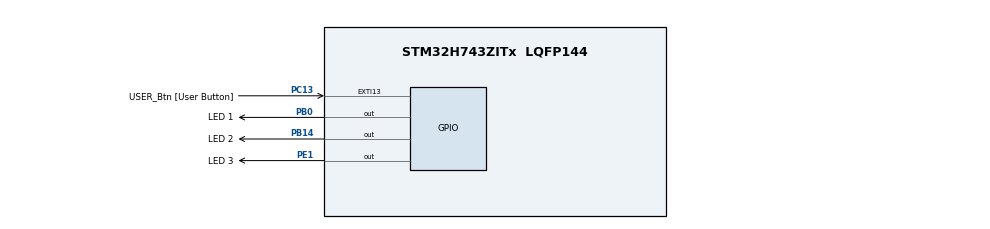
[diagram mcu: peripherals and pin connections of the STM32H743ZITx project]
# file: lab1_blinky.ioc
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CORTEX_M7.default_mode_Activation=1
Mcu.Family=STM32H7
Mcu.Name=STM32H743ZITx
Mcu.Package=LQFP144
NVIC.PriorityGroup=NVIC_PRIORITYGROUP_4
PA13\ (JTMS/SWDIO).GPIO_Label=TMS
PA13\ (JTMS/SWDIO).Signal=DEBUG_JTMS-SWDIO
PA14\ (JTCK/SWCLK).GPIO_Label=TCK
PA14\ (JTCK/SWCLK).Signal=DEBUG_JTCK-SWCLK
PB0.GPIO_Label=LED 1
PB0.GPIO_Speed=GPIO_SPEED_FREQ_HIGH
PB0.PinState=GPIO_PIN_SET
PB0.Signal=GPIO_Output
PB14.GPIO_Label=LED 2
PB14.GPIO_Speed=GPIO_SPEED_FREQ_HIGH
PB14.PinState=GPIO_PIN_SET
PB14.Signal=GPIO_Output
PB3\ (JTDO/TRACESWO).GPIO_Label=SWO
PB3\ (JTDO/TRACESWO).Signal=DEBUG_JTDO-SWO
PC13.GPIO_Label=USER_Btn [User Button]
PC13.Signal=GPXTI13
PC14-OSC32_IN\ (OSC32_IN).Signal=RCC_OSC32_IN
PC15-OSC32_OUT\ (OSC32_OUT).Signal=RCC_OSC32_OUT
PD8.GPIO_Label=STLK_RX [STM32F103CBT6_PA3]
PD8.Signal=USART3_TX
PD9.GPIO_Label=STLK_TX [STM32F103CBT6_PA2]
PD9.Signal=USART3_RX
PE1.GPIO_Label=LED 3
PE1.GPIO_Speed=GPIO_SPEED_FREQ_HIGH
PE1.PinState=GPIO_PIN_SET
PE1.Signal=GPIO_Output
PH0-OSC_IN\ (PH0).Mode=HSE-External-Oscillator
PH0-OSC_IN\ (PH0).Signal=RCC_OSC_IN
PH1-OSC_OUT\ (PH1).Mode=HSE-External-Oscillator
PH1-OSC_OUT\ (PH1).Signal=RCC_OSC_OUT
ProjectManager.HeapSize=0x200
ProjectManager.StackSize=0x400
ProjectManager.TargetToolchain=STM32CubeIDE
RCC.48MHZClocksFreq_Value=24000000
RCC.ADCFreq_Value=16125000
RCC.AHBFreq_Value=216000000
RCC.APB1CLKDivider=RCC_HCLK_DIV4
RCC.APB1Freq_Value=120000000
RCC.APB1TimFreq_Value=108000000
RCC.APB2CLKDivider=RCC_HCLK_DIV2
RCC.APB2Freq_Value=120000000
RCC.APB2TimFreq_Value=216000000
RCC.APB3Freq_Value=120000000
RCC.APB4Freq_Value=120000000
RCC.CortexFreq_Value=480000000
RCC.D1PPRE=RCC_APB3_DIV2
RCC.D2PPRE1=RCC_APB1_DIV2
RCC.D2PPRE2=RCC_APB2_DIV2
RCC.D3PPRE=RCC_APB4_DIV2
RCC.DIVM1=1
RCC.DIVN1=120
RCC.DIVQ1=4
RCC.HCLKFreq_Value=240000000
RCC.HPRE=RCC_HCLK_DIV2
RCC.HSE_VALUE=8000000
RCC.HSI_VALUE=64000000
RCC.PLLFRACN=0
RCC.PLLM=25
RCC.PLLMUL=RCC_PLL_MUL9
RCC.PLLN=432
RCC.PLLQ=9
RCC.PLLSourceVirtual=RCC_PLLSOURCE_HSE
RCC.PRESCALERUSB=RCC_USBCLKSOURCE_PLL_DIV1_5
RCC.PWR_Regulator_Voltage_Scale=PWR_REGULATOR_VOLTAGE_SCALE0
RCC.SYSCLKFreq_VALUE=480000000
RCC.SYSCLKSource=RCC_SYSCLKSOURCE_PLLCLK
RCC.SYSCLKSourceVirtual=RCC_SYSCLKSOURCE_PLLCLK
RCC.USBFreq_Value=240000000
RCC.VCOOutputFreq_Value=432000000
VP_MEMORYMAP_VS_MEMORYMAP.Mode=CurAppReg
board=NUCLEO-H743ZI

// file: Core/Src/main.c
/* USER CODE BEGIN Header */
/**
  ******************************************************************************
  * @file           : main.c
  * @brief          : Main program body
  ******************************************************************************
  * @attention
  *
  * Copyright (c) 2025 STMicroelectronics.
  * All rights reserved.
  *
  * This software is licensed under terms that can be found in the LICENSE file
  * in the root directory of this software component.
  * If no LICENSE file comes with this software, it is provided AS-IS.
  *
  ******************************************************************************
  */
/* USER CODE END Header */
#include "main.h"

void SystemClock_Config(void);
static void MPU_Config(void);
static void MX_GPIO_Init(void);

int main(void)
{

  /* MPU Configuration--------------------------------------------------------*/
  MPU_Config();

  /* MCU Configuration--------------------------------------------------------*/

  /* Reset of all peripherals, Initializes the Flash interface and the Systick. */
  HAL_Init();

  /* Configure the system clock */
  SystemClock_Config();

  /* Initialize all configured peripherals */
  MX_GPIO_Init();

  /* Infinite loop */
  while (1)
  {

    /* USER CODE BEGIN 3 */
	  HAL_GPIO_TogglePin(LED_1_GPIO_Port, LED_1_Pin);
	  	HAL_Delay(100);
	  	HAL_GPIO_TogglePin(LED_2_GPIO_Port, LED_2_Pin);
	  	HAL_Delay(100);
	  	HAL_GPIO_TogglePin(LED_3_GPIO_Port, LED_3_Pin);
	  	HAL_Delay(100);
  }
  /* USER CODE END 3 */
}

void SystemClock_Config(void)
{
  RCC_OscInitTypeDef RCC_OscInitStruct = {0};
  RCC_ClkInitTypeDef RCC_ClkInitStruct = {0};

  /** Supply configuration update enable
  */
  HAL_PWREx_ConfigSupply(PWR_LDO_SUPPLY);

  /** Configure the main internal regulator output voltage
  */
  __HAL_PWR_VOLTAGESCALING_CONFIG(PWR_REGULATOR_VOLTAGE_SCALE0);

  while(!__HAL_PWR_GET_FLAG(PWR_FLAG_VOSRDY)) {}

  /** Initializes the RCC Oscillators according to the specified parameters
  * in the RCC_OscInitTypeDef structure.
  */
  RCC_OscInitStruct.OscillatorType = RCC_OSCILLATORTYPE_HSE;
  RCC_OscInitStruct.HSEState = RCC_HSE_ON;
  RCC_OscInitStruct.PLL.PLLState = RCC_PLL_ON;
  RCC_OscInitStruct.PLL.PLLSource = RCC_PLLSOURCE_HSE;
  RCC_OscInitStruct.PLL.PLLM = 1;
  RCC_OscInitStruct.PLL.PLLN = 120;
  RCC_OscInitStruct.PLL.PLLP = 2;
  RCC_OscInitStruct.PLL.PLLQ = 4;
  RCC_OscInitStruct.PLL.PLLR = 2;
  RCC_OscInitStruct.PLL.PLLRGE = RCC_PLL1VCIRANGE_3;
  RCC_OscInitStruct.PLL.PLLVCOSEL = RCC_PLL1VCOWIDE;
  RCC_OscInitStruct.PLL.PLLFRACN = 0;
  if (HAL_RCC_OscConfig(&RCC_OscInitStruct) != HAL_OK)
  {
    Error_Handler();
  }

  /** Initializes the CPU, AHB and APB buses clocks
  */
  RCC_ClkInitStruct.ClockType = RCC_CLOCKTYPE_HCLK|RCC_CLOCKTYPE_SYSCLK
                              |RCC_CLOCKTYPE_PCLK1|RCC_CLOCKTYPE_PCLK2
                              |RCC_CLOCKTYPE_D3PCLK1|RCC_CLOCKTYPE_D1PCLK1;
  RCC_ClkInitStruct.SYSCLKSource = RCC_SYSCLKSOURCE_PLLCLK;
  RCC_ClkInitStruct.SYSCLKDivider = RCC_SYSCLK_DIV1;
  RCC_ClkInitStruct.AHBCLKDivider = RCC_HCLK_DIV2;
  RCC_ClkInitStruct.APB3CLKDivider = RCC_APB3_DIV2;
  RCC_ClkInitStruct.APB1CLKDivider = RCC_APB1_DIV2;
  RCC_ClkInitStruct.APB2CLKDivider = RCC_APB2_DIV2;
  RCC_ClkInitStruct.APB4CLKDivider = RCC_APB4_DIV2;

  if (HAL_RCC_ClockConfig(&RCC_ClkInitStruct, FLASH_LATENCY_4) != HAL_OK)
  {
    Error_Handler();
  }
}

static void MX_GPIO_Init(void)
{
  GPIO_InitTypeDef GPIO_InitStruct = {0};

  /* GPIO Ports Clock Enable */
  __HAL_RCC_GPIOC_CLK_ENABLE();
  __HAL_RCC_GPIOH_CLK_ENABLE();
  __HAL_RCC_GPIOB_CLK_ENABLE();
  __HAL_RCC_GPIOD_CLK_ENABLE();
  __HAL_RCC_GPIOA_CLK_ENABLE();
  __HAL_RCC_GPIOE_CLK_ENABLE();

  /*Configure GPIO pin Output Level */
  HAL_GPIO_WritePin(GPIOB, LED_1_Pin|LED_2_Pin, GPIO_PIN_SET);

  /*Configure GPIO pin Output Level */
  HAL_GPIO_WritePin(LED_3_GPIO_Port, LED_3_Pin, GPIO_PIN_SET);

  /*Configure GPIO pin : USER_Btn_Pin */
  GPIO_InitStruct.Pin = USER_Btn_Pin;
  GPIO_InitStruct.Mode = GPIO_MODE_IT_RISING;
  GPIO_InitStruct.Pull = GPIO_NOPULL;
  HAL_GPIO_Init(USER_Btn_GPIO_Port, &GPIO_InitStruct);

  /*Configure GPIO pins : LED_1_Pin LED_2_Pin */
  GPIO_InitStruct.Pin = LED_1_Pin|LED_2_Pin;
  GPIO_InitStruct.Mode = GPIO_MODE_OUTPUT_PP;
  GPIO_InitStruct.Pull = GPIO_NOPULL;
  GPIO_InitStruct.Speed = GPIO_SPEED_FREQ_HIGH;
  HAL_GPIO_Init(GPIOB, &GPIO_InitStruct);

  /*Configure GPIO pins : STLK_RX_Pin STLK_TX_Pin */
  GPIO_InitStruct.Pin = STLK_RX_Pin|STLK_TX_Pin;
  GPIO_InitStruct.Mode = GPIO_MODE_AF_PP;
  GPIO_InitStruct.Pull = GPIO_NOPULL;
  GPIO_InitStruct.Speed = GPIO_SPEED_FREQ_LOW;
  GPIO_InitStruct.Alternate = GPIO_AF7_USART3;
  HAL_GPIO_Init(GPIOD, &GPIO_InitStruct);

  /*Configure GPIO pin : LED_3_Pin */
  GPIO_InitStruct.Pin = LED_3_Pin;
  GPIO_InitStruct.Mode = GPIO_MODE_OUTPUT_PP;
  GPIO_InitStruct.Pull = GPIO_NOPULL;
  GPIO_InitStruct.Speed = GPIO_SPEED_FREQ_HIGH;
  HAL_GPIO_Init(LED_3_GPIO_Port, &GPIO_InitStruct);

}

 /* MPU Configuration */

void MPU_Config(void)
{
  MPU_Region_InitTypeDef MPU_InitStruct = {0};

  /* Disables the MPU */
  HAL_MPU_Disable();

  /** Initializes and configures the Region and the memory to be protected
  */
  MPU_InitStruct.Enable = MPU_REGION_ENABLE;
  MPU_InitStruct.Number = MPU_REGION_NUMBER0;
  MPU_InitStruct.BaseAddress = 0x0;
  MPU_InitStruct.Size = MPU_REGION_SIZE_4GB;
  MPU_InitStruct.SubRegionDisable = 0x87;
  MPU_InitStruct.TypeExtField = MPU_TEX_LEVEL0;
  MPU_InitStruct.AccessPermission = MPU_REGION_NO_ACCESS;
  MPU_InitStruct.DisableExec = MPU_INSTRUCTION_ACCESS_DISABLE;
  MPU_InitStruct.IsShareable = MPU_ACCESS_SHAREABLE;
  MPU_InitStruct.IsCacheable = MPU_ACCESS_NOT_CACHEABLE;
  MPU_InitStruct.IsBufferable = MPU_ACCESS_NOT_BUFFERABLE;

  HAL_MPU_ConfigRegion(&MPU_InitStruct);
  /* Enables the MPU */
  HAL_MPU_Enable(MPU_PRIVILEGED_DEFAULT);

}

void Error_Handler(void)
{
  __disable_irq();
  while (1)
  {
  }
}
